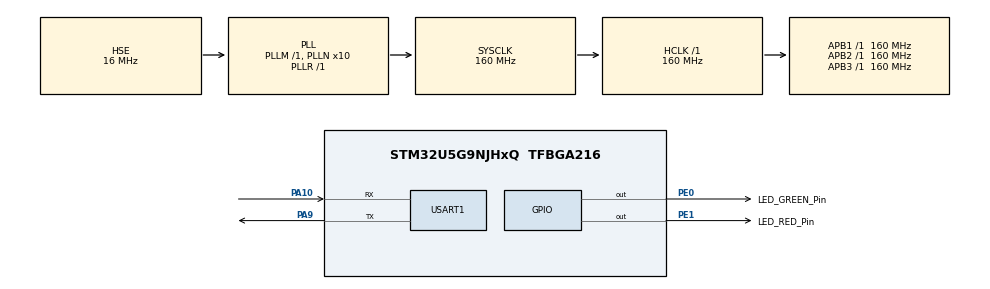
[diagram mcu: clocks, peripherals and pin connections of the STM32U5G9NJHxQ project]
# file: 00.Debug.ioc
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CORTEX_M33_NS.userName=CORTEX_M33
Mcu.Family=STM32U5
Mcu.Name=STM32U5G9NJHxQ
Mcu.Package=TFBGA216
NVIC.PriorityGroup=NVIC_PRIORITYGROUP_4
NVIC.USART1_IRQn=true\:0\:0\:false\:false\:true\:true\:true\:true
PA10.Mode=Asynchronous
PA10.Signal=USART1_RX
PA9.Mode=Asynchronous
PA9.Signal=USART1_TX
PC14-OSC32_IN\ (PC14).Mode=LSE-External-Oscillator
PC14-OSC32_IN\ (PC14).Signal=RCC_OSC32_IN
PC15-OSC32_OUT\ (PC15).Mode=LSE-External-Oscillator
PC15-OSC32_OUT\ (PC15).Signal=RCC_OSC32_OUT
PE0.GPIO_Label=LED_GREEN_Pin
PE0.Signal=GPIO_Output
PE1.GPIO_Label=LED_RED_Pin
PE1.Signal=GPIO_Output
PH0-OSC_IN\ (PH0).Mode=HSE-External-Oscillator
PH0-OSC_IN\ (PH0).Signal=RCC_OSC_IN
PH1-OSC_OUT\ (PH1).Mode=HSE-External-Oscillator
PH1-OSC_OUT\ (PH1).Signal=RCC_OSC_OUT
PWR.PowerMode=PWR_SMPS_SUPPLY
ProjectManager.HeapSize=0x200
ProjectManager.StackSize=0x400
ProjectManager.TargetToolchain=STM32CubeIDE
RCC.ADCFreq_Value=16000000
RCC.AHBFreq_Value=160000000
RCC.APB1Freq_Value=160000000
RCC.APB1TimFreq_Value=160000000
RCC.APB2Freq_Value=160000000
RCC.APB2TimFreq_Value=160000000
RCC.APB3Freq_Value=160000000
RCC.CortexFreq_Value=160000000
RCC.EPOD_VALUE=16000000
RCC.HCLKFreq_Value=160000000
RCC.HSE_VALUE=16000000
RCC.HSI48_VALUE=48000000
RCC.HSI_VALUE=16000000
RCC.LSIDIV_VALUE=32000
RCC.MSIClockRange=RCC_MSIRANGE_0
RCC.MSI_VALUE=48000000
RCC.PLL1R=1
RCC.PLL2FRACN=0
RCC.PLL3FRACN=0
RCC.PLLFRACN=0
RCC.PLLN=10
RCC.PLLSourceVirtual=RCC_PLLSOURCE_HSE
RCC.SYSCLKFreq_VALUE=160000000
RCC.SYSCLKSource=RCC_SYSCLKSOURCE_PLLCLK
RCC.VCOOutputFreq_Value=160000000
USART1.VirtualMode-Asynchronous=VM_ASYNC
VP_ICACHE_VS_ICACHE.Mode=DirectMappedCache
VP_LPBAMQUEUE_VS_QUEUE.Mode=QUEUEMODE
VP_LPBAM_VS_SIG1.Mode=SmartRun
VP_LPBAM_VS_SIG4.Mode=LPDMA1
VP_MEMORYMAP_VS_MEMORYMAP.Mode=CurAppReg
VP_PWR_VS_DBSignals.Mode=DisableDeadBatterySignals
VP_PWR_VS_LPOM.Mode=PowerOptimisation
VP_PWR_VS_SECSignals.Mode=Security/Privilege
board=custom

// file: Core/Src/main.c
/* USER CODE BEGIN Header */
/**
  ******************************************************************************
  * @file           : main.c
  * @brief          : Main program body
  ******************************************************************************
  * @attention
  *
  * Copyright (c) 2024 STMicroelectronics.
  * All rights reserved.
  *
  * This software is licensed under terms that can be found in the LICENSE file
  * in the root directory of this software component.
  * If no LICENSE file comes with this software, it is provided AS-IS.
  *
  ******************************************************************************
  */
/* USER CODE END Header */
#include "main.h"

/* USER CODE BEGIN Includes */
#include "stdio.h"
#include "string.h"
/* USER CODE END Includes */

UART_HandleTypeDef huart1;

/* USER CODE BEGIN PV */
int count = 0;
/* USER CODE END PV */

void SystemClock_Config(void);
static void SystemPower_Config(void);
static void MX_GPIO_Init(void);
static void MX_USART1_UART_Init(void);
static void MX_ICACHE_Init(void);

/* USER CODE BEGIN 0 */
int _write(int file, char* pData, int len)
{
	HAL_UART_Transmit(&huart1, (uint8_t*)pData, len, 10);
	return len;
}
/* USER CODE END 0 */

int main(void)
{

  /* MCU Configuration--------------------------------------------------------*/

  /* Reset of all peripherals, Initializes the Flash interface and the Systick. */
  HAL_Init();

  /* Configure the System Power */
  SystemPower_Config();

  /* Configure the system clock */
  SystemClock_Config();

  /* Initialize all configured peripherals */
  MX_GPIO_Init();
  MX_USART1_UART_Init();
  MX_ICACHE_Init();

  /* Infinite loop */
  /* USER CODE BEGIN WHILE */
  while (1)
  {
	  count++;
	  printf("[%d]\r\n", count);
	  HAL_GPIO_TogglePin(GPIOE, LED_RED_Pin_Pin);
	  HAL_Delay(1000);
    /* USER CODE END WHILE */

  }
}

void SystemClock_Config(void)
{
  RCC_OscInitTypeDef RCC_OscInitStruct = {0};
  RCC_ClkInitTypeDef RCC_ClkInitStruct = {0};

  /** Configure the main internal regulator output voltage
  */
  if (HAL_PWREx_ControlVoltageScaling(PWR_REGULATOR_VOLTAGE_SCALE1) != HAL_OK)
  {
    Error_Handler();
  }

  /** Initializes the CPU, AHB and APB buses clocks
  */
  RCC_OscInitStruct.OscillatorType = RCC_OSCILLATORTYPE_HSE;
  RCC_OscInitStruct.HSEState = RCC_HSE_ON;
  RCC_OscInitStruct.PLL.PLLState = RCC_PLL_ON;
  RCC_OscInitStruct.PLL.PLLSource = RCC_PLLSOURCE_HSE;
  RCC_OscInitStruct.PLL.PLLMBOOST = RCC_PLLMBOOST_DIV1;
  RCC_OscInitStruct.PLL.PLLM = 1;
  RCC_OscInitStruct.PLL.PLLN = 10;
  RCC_OscInitStruct.PLL.PLLP = 2;
  RCC_OscInitStruct.PLL.PLLQ = 2;
  RCC_OscInitStruct.PLL.PLLR = 1;
  RCC_OscInitStruct.PLL.PLLRGE = RCC_PLLVCIRANGE_1;
  RCC_OscInitStruct.PLL.PLLFRACN = 0;
  if (HAL_RCC_OscConfig(&RCC_OscInitStruct) != HAL_OK)
  {
    Error_Handler();
  }

  /** Initializes the CPU, AHB and APB buses clocks
  */
  RCC_ClkInitStruct.ClockType = RCC_CLOCKTYPE_HCLK|RCC_CLOCKTYPE_SYSCLK
                              |RCC_CLOCKTYPE_PCLK1|RCC_CLOCKTYPE_PCLK2
                              |RCC_CLOCKTYPE_PCLK3;
  RCC_ClkInitStruct.SYSCLKSource = RCC_SYSCLKSOURCE_PLLCLK;
  RCC_ClkInitStruct.AHBCLKDivider = RCC_SYSCLK_DIV1;
  RCC_ClkInitStruct.APB1CLKDivider = RCC_HCLK_DIV1;
  RCC_ClkInitStruct.APB2CLKDivider = RCC_HCLK_DIV1;
  RCC_ClkInitStruct.APB3CLKDivider = RCC_HCLK_DIV1;

  if (HAL_RCC_ClockConfig(&RCC_ClkInitStruct, FLASH_LATENCY_4) != HAL_OK)
  {
    Error_Handler();
  }
}

/**
  * @brief Power Configuration
  * @retval None
  */
static void SystemPower_Config(void)
{

  /*
   * Disable the internal Pull-Up in Dead Battery pins of UCPD peripheral
   */
  HAL_PWREx_DisableUCPDDeadBattery();

  /*
   * Switch to SMPS regulator instead of LDO
   */
  if (HAL_PWREx_ConfigSupply(PWR_SMPS_SUPPLY) != HAL_OK)
  {
    Error_Handler();
  }
}

static void MX_ICACHE_Init(void)
{

  /** Enable instruction cache in 1-way (direct mapped cache)
  */
  if (HAL_ICACHE_ConfigAssociativityMode(ICACHE_1WAY) != HAL_OK)
  {
    Error_Handler();
  }
  if (HAL_ICACHE_Enable() != HAL_OK)
  {
    Error_Handler();
  }

}

static void MX_USART1_UART_Init(void)
{

  huart1.Instance = USART1;
  huart1.Init.BaudRate = 115200;
  huart1.Init.WordLength = UART_WORDLENGTH_8B;
  huart1.Init.StopBits = UART_STOPBITS_1;
  huart1.Init.Parity = UART_PARITY_NONE;
  huart1.Init.Mode = UART_MODE_TX_RX;
  huart1.Init.HwFlowCtl = UART_HWCONTROL_NONE;
  huart1.Init.OverSampling = UART_OVERSAMPLING_16;
  huart1.Init.OneBitSampling = UART_ONE_BIT_SAMPLE_DISABLE;
  huart1.Init.ClockPrescaler = UART_PRESCALER_DIV1;
  huart1.AdvancedInit.AdvFeatureInit = UART_ADVFEATURE_NO_INIT;
  if (HAL_UART_Init(&huart1) != HAL_OK)
  {
    Error_Handler();
  }
  if (HAL_UARTEx_SetTxFifoThreshold(&huart1, UART_TXFIFO_THRESHOLD_1_8) != HAL_OK)
  {
    Error_Handler();
  }
  if (HAL_UARTEx_SetRxFifoThreshold(&huart1, UART_RXFIFO_THRESHOLD_1_8) != HAL_OK)
  {
    Error_Handler();
  }
  if (HAL_UARTEx_DisableFifoMode(&huart1) != HAL_OK)
  {
    Error_Handler();
  }

}

static void MX_GPIO_Init(void)
{
  GPIO_InitTypeDef GPIO_InitStruct = {0};

  /* GPIO Ports Clock Enable */
  __HAL_RCC_GPIOE_CLK_ENABLE();
  __HAL_RCC_GPIOC_CLK_ENABLE();
  __HAL_RCC_GPIOA_CLK_ENABLE();
  __HAL_RCC_GPIOH_CLK_ENABLE();

  /*Configure GPIO pin Output Level */
  HAL_GPIO_WritePin(GPIOE, LED_GREEN_Pin_Pin|LED_RED_Pin_Pin, GPIO_PIN_RESET);

  /*Configure GPIO pins : LED_GREEN_Pin_Pin LED_RED_Pin_Pin */
  GPIO_InitStruct.Pin = LED_GREEN_Pin_Pin|LED_RED_Pin_Pin;
  GPIO_InitStruct.Mode = GPIO_MODE_OUTPUT_PP;
  GPIO_InitStruct.Pull = GPIO_NOPULL;
  GPIO_InitStruct.Speed = GPIO_SPEED_FREQ_LOW;
  HAL_GPIO_Init(GPIOE, &GPIO_InitStruct);

}

void Error_Handler(void)
{
  __disable_irq();
  while (1)
  {
  }
}
